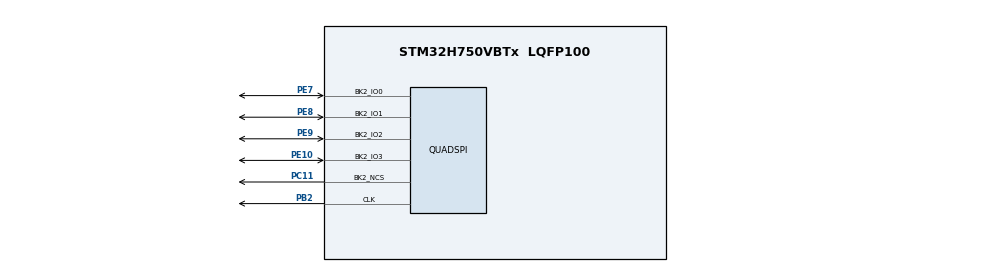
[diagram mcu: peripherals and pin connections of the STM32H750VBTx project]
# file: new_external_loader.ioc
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CORTEX_M7.default_mode_Activation=0
Mcu.Family=STM32H7
Mcu.Name=STM32H750VBTx
Mcu.Package=LQFP100
NVIC.PriorityGroup=NVIC_PRIORITYGROUP_4
NVIC.TIM2_IRQn=true\:15\:0\:false\:false\:true\:false\:true\:true
NVIC.TimeBase=TIM2_IRQn
NVIC.TimeBaseIP=TIM2
PA13\ (JTMS/SWDIO).Mode=Trace_Asynchronous_SW
PA13\ (JTMS/SWDIO).Signal=DEBUG_JTMS-SWDIO
PA14\ (JTCK/SWCLK).Mode=Trace_Asynchronous_SW
PA14\ (JTCK/SWCLK).Signal=DEBUG_JTCK-SWCLK
PB2.GPIO_Speed=GPIO_SPEED_FREQ_LOW
PB2.Mode=Single Bank 2
PB2.Signal=QUADSPI_CLK
PB3\ (JTDO/TRACESWO).Mode=Trace_Asynchronous_SW
PB3\ (JTDO/TRACESWO).Signal=DEBUG_JTDO-SWO
PC11.GPIO_Speed=GPIO_SPEED_FREQ_LOW
PC11.Mode=Single Bank 2
PC11.Signal=QUADSPI_BK2_NCS
PE10.GPIO_Speed=GPIO_SPEED_FREQ_LOW
PE10.Mode=Single Bank 2
PE10.Signal=QUADSPI_BK2_IO3
PE7.GPIO_Speed=GPIO_SPEED_FREQ_LOW
PE7.Mode=Single Bank 2
PE7.Signal=QUADSPI_BK2_IO0
PE8.GPIO_Speed=GPIO_SPEED_FREQ_LOW
PE8.Mode=Single Bank 2
PE8.Signal=QUADSPI_BK2_IO1
PE9.GPIO_Speed=GPIO_SPEED_FREQ_LOW
PE9.Mode=Single Bank 2
PE9.Signal=QUADSPI_BK2_IO2
ProjectManager.HeapSize=0x200
ProjectManager.StackSize=0x400
ProjectManager.TargetToolchain=STM32CubeIDE
QUADSPI.ChipSelectHighTime=QSPI_CS_HIGH_TIME_1_CYCLE
QUADSPI.ClockPrescaler=1
QUADSPI.FifoThreshold=4
QUADSPI.FlashSize=24
QUADSPI.SampleShifting=QSPI_SAMPLE_SHIFTING_HALFCYCLE
RCC.ADCFreq_Value=72299804.6875
RCC.APB1Freq_Value=32000000
RCC.APB2Freq_Value=32000000
RCC.APB3Freq_Value=32000000
RCC.APB4Freq_Value=64000000
RCC.CortexFreq_Value=64000000
RCC.D1PPRE=RCC_APB3_DIV2
RCC.D2PPRE1=RCC_APB1_DIV2
RCC.D2PPRE2=RCC_APB2_DIV2
RCC.DIVM1=4
RCC.DIVM2=4
RCC.DIVN1=9
RCC.DIVN2=9
RCC.HCLKFreq_Value=64000000
RCC.PLL2FRACN=307
RCC.PLLFRACN=3307
RCC.PWR_Regulator_Voltage_Scale=PWR_REGULATOR_VOLTAGE_SCALE1
RCC.SYSCLKFreq_VALUE=64000000
RCC.SupplySource=PWR_EXTERNAL_SOURCE_SUPPLY
RCC.USBFreq_Value=75229492.1875
RCC.VDD_VALUE=3.07
VP_SYS_VS_tim2.Mode=TIM2
board=custom

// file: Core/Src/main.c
/* USER CODE BEGIN Header */
/**
  ******************************************************************************
  * @file           : main.c
  * @brief          : Main program body
  ******************************************************************************
  * @attention
  *
  * Copyright (c) 2023 STMicroelectronics.
  * All rights reserved.
  *
  * This software is licensed under terms that can be found in the LICENSE file
  * in the root directory of this software component.
  * If no LICENSE file comes with this software, it is provided AS-IS.
  *
  ******************************************************************************
  */
/* USER CODE END Header */
#include "main.h"
#include "quadspi.h"
#include "gpio.h"

/* USER CODE BEGIN Includes */
#include "stdio.h"
/* USER CODE END Includes */

void SystemClock_Config(void);

int main(void)
{

  /* MCU Configuration--------------------------------------------------------*/

  /* Reset of all peripherals, Initializes the Flash interface and the Systick. */
  HAL_Init();

  /* Configure the system clock */
  SystemClock_Config();

  /* Initialize all configured peripherals */
  MX_GPIO_Init();
  MX_QUADSPI_Init();
  /* USER CODE BEGIN 2 */

  /* USER CODE BEGIN 2 */
CSP_QUADSPI_Init();

      if (CSP_QSPI_EnableMemoryMappedMode()!= HAL_OK) {

          while (1)
              ;  //breakpoint - error detected
      }

  /* USER CODE END 2 */

  /* Infinite loop */
  while (1)
  {

  }
}

void SystemClock_Config(void)
{
  RCC_OscInitTypeDef RCC_OscInitStruct = {0};
  RCC_ClkInitTypeDef RCC_ClkInitStruct = {0};

  /** Supply configuration update enable
  */
  HAL_PWREx_ConfigSupply(PWR_EXTERNAL_SOURCE_SUPPLY);

  /** Configure the main internal regulator output voltage
  */
  __HAL_PWR_VOLTAGESCALING_CONFIG(PWR_REGULATOR_VOLTAGE_SCALE1);

  while(!__HAL_PWR_GET_FLAG(PWR_FLAG_VOSRDY)) {}

  /** Initializes the RCC Oscillators according to the specified parameters
  * in the RCC_OscInitTypeDef structure.
  */
  RCC_OscInitStruct.OscillatorType = RCC_OSCILLATORTYPE_HSI;
  RCC_OscInitStruct.HSIState = RCC_HSI_DIV1;
  RCC_OscInitStruct.HSICalibrationValue = RCC_HSICALIBRATION_DEFAULT;
  RCC_OscInitStruct.PLL.PLLState = RCC_PLL_NONE;
  if (HAL_RCC_OscConfig(&RCC_OscInitStruct) != HAL_OK)
  {
    Error_Handler();
  }

  /** Initializes the CPU, AHB and APB buses clocks
  */
  RCC_ClkInitStruct.ClockType = RCC_CLOCKTYPE_HCLK|RCC_CLOCKTYPE_SYSCLK
                              |RCC_CLOCKTYPE_PCLK1|RCC_CLOCKTYPE_PCLK2
                              |RCC_CLOCKTYPE_D3PCLK1|RCC_CLOCKTYPE_D1PCLK1;
  RCC_ClkInitStruct.SYSCLKSource = RCC_SYSCLKSOURCE_HSI;
  RCC_ClkInitStruct.SYSCLKDivider = RCC_SYSCLK_DIV1;
  RCC_ClkInitStruct.AHBCLKDivider = RCC_HCLK_DIV1;
  RCC_ClkInitStruct.APB3CLKDivider = RCC_APB3_DIV2;
  RCC_ClkInitStruct.APB1CLKDivider = RCC_APB1_DIV2;
  RCC_ClkInitStruct.APB2CLKDivider = RCC_APB2_DIV2;
  RCC_ClkInitStruct.APB4CLKDivider = RCC_APB4_DIV1;

  if (HAL_RCC_ClockConfig(&RCC_ClkInitStruct, FLASH_LATENCY_0) != HAL_OK)
  {
    Error_Handler();
  }
}

void HAL_TIM_PeriodElapsedCallback(TIM_HandleTypeDef *htim)
{
  if (htim->Instance == TIM2) {
    HAL_IncTick();
  }
}

void Error_Handler(void)
{
  __disable_irq();
  while (1)
  {
  }
}
